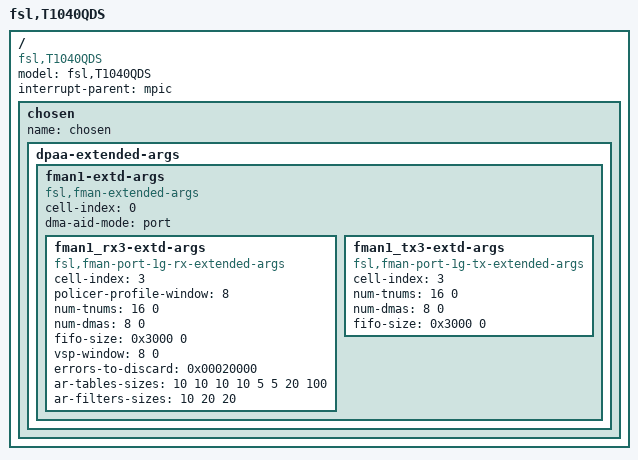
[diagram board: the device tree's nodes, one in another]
/*
 * T1040QDS Deep Sleep Auto Response Device Tree Source
 *
 * Copyright 2014 Freescale Semiconductor Inc.
 *
 * Redistribution and use in source and binary forms, with or without
 * modification, are permitted provided that the following conditions are met:
 *     * Redistributions of source code must retain the above copyright
 *	 notice, this list of conditions and the following disclaimer.
 *     * Redistributions in binary form must reproduce the above copyright
 *	 notice, this list of conditions and the following disclaimer in the
 *	 documentation and/or other materials provided with the distribution.
 *     * Neither the name of Freescale Semiconductor nor the
 *	 names of its contributors may be used to endorse or promote products
 *	 derived from this software without specific prior written permission.
 *
 *
 * ALTERNATIVELY, this software may be distributed under the terms of the
 * GNU General Public License ("GPL") as published by the Free Software
 * Foundation, either version 2 of that License or (at your option) any
 * later version.
 *
 * THIS SOFTWARE IS PROVIDED BY Freescale Semiconductor "AS IS" AND ANY
 * EXPRESS OR IMPLIED WARRANTIES, INCLUDING, BUT NOT LIMITED TO, THE IMPLIED
 * WARRANTIES OF MERCHANTABILITY AND FITNESS FOR A PARTICULAR PURPOSE ARE
 * DISCLAIMED. IN NO EVENT SHALL Freescale Semiconductor BE LIABLE FOR ANY
 * DIRECT, INDIRECT, INCIDENTAL, SPECIAL, EXEMPLARY, OR CONSEQUENTIAL DAMAGES
 * (INCLUDING, BUT NOT LIMITED TO, PROCUREMENT OF SUBSTITUTE GOODS OR SERVICES;
 * LOSS OF USE, DATA, OR PROFITS; OR BUSINESS INTERRUPTION) HOWEVER CAUSED AND
 * ON ANY THEORY OF LIABILITY, WHETHER IN CONTRACT, STRICT LIABILITY, OR TORT
 * (INCLUDING NEGLIGENCE OR OTHERWISE) ARISING IN ANY WAY OUT OF THE USE OF THIS
 * SOFTWARE, EVEN IF ADVISED OF THE POSSIBILITY OF SUCH DAMAGE.
 */

/include/ "fsl/t104xsi-pre.dtsi"
/include/ "t104xqds.dtsi"

/ {
	model = "fsl,T1040QDS";
	compatible = "fsl,T1040QDS";
	interrupt-parent = <&mpic>;
	chosen {
	    name = "chosen";

	    dpaa-extended-args {
		fman1-extd-args {
		    cell-index = <0>;
		    compatible = "fsl,fman-extended-args";
		    dma-aid-mode = "port";

		    fman1_rx3-extd-args {
			cell-index = <3>;
			compatible = "fsl,fman-port-1g-rx-extended-args";
			policer-profile-window = <8>;
			num-tnums = <16 0>;
			num-dmas = <8 0>;
			fifo-size = <0x3000 0>;
			vsp-window = <8 0>;
			errors-to-discard = <0x00020000>;
			ar-tables-sizes = <10 10 10 10 5 5 20 100>;
			ar-filters-sizes = <10 20 20>;
		    };

		    fman1_tx3-extd-args {
			cell-index = <3>;
			compatible = "fsl,fman-port-1g-tx-extended-args";
			num-tnums = <16 0>;
			num-dmas = <8 0>;
			fifo-size = <0x3000 0>;
		    };

		};
	    };
	};
};

/include/ "fsl/t1040si-post.dtsi"
/include/ "fsl/qoriq-dpaa-res3.dtsi"


